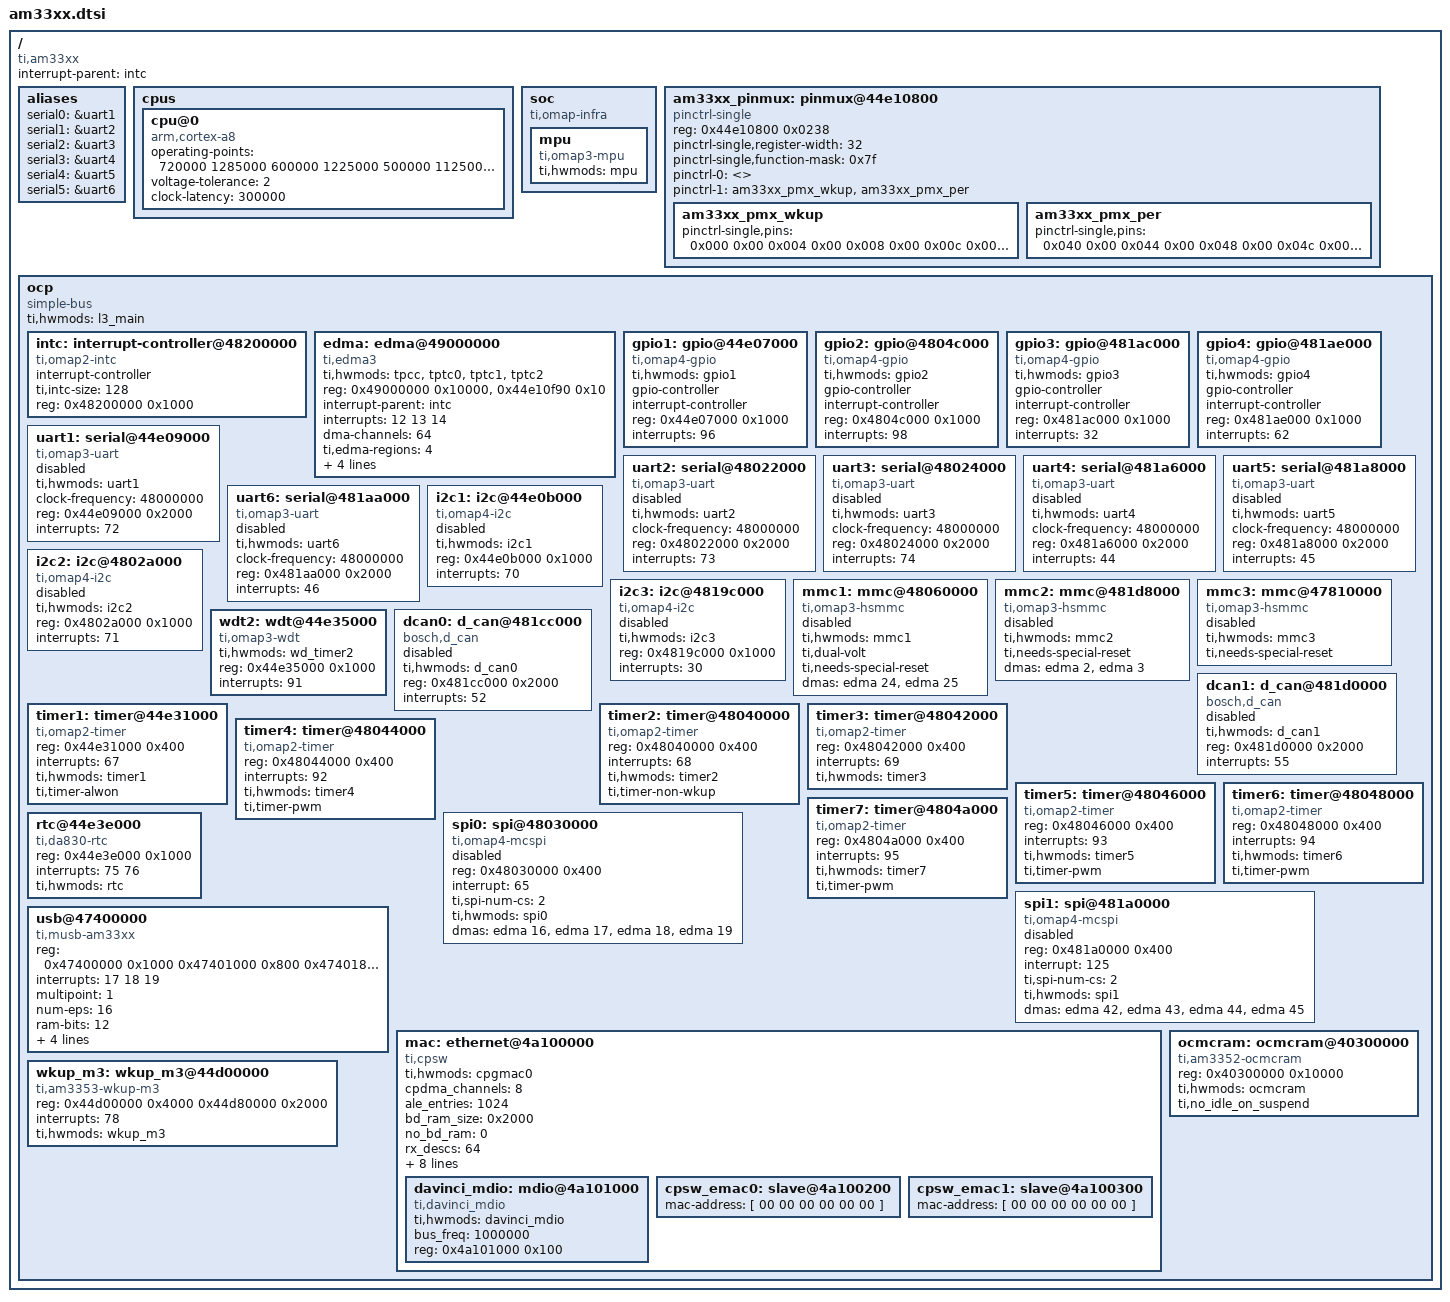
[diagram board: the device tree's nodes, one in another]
/*
 * Device Tree Source for AM33XX SoC
 *
 * Copyright (C) 2012 Texas Instruments Incorporated - http://www.ti.com/
 *
 * This file is licensed under the terms of the GNU General Public License
 * version 2.  This program is licensed "as is" without any warranty of any
 * kind, whether express or implied.
 */

/include/ "skeleton.dtsi"

/ {
	compatible = "ti,am33xx";
	interrupt-parent = <&intc>;

	aliases {
		serial0 = &uart1;
		serial1 = &uart2;
		serial2 = &uart3;
		serial3 = &uart4;
		serial4 = &uart5;
		serial5 = &uart6;
	};

	cpus {
		cpu@0 {
			compatible = "arm,cortex-a8";

			/*
			 * To consider voltage drop between PMIC and SoC,
			 * tolerance value is reduced to 2% from 4% and
			 * voltage value is increased as a precaution.
			 */
			operating-points = <
				/* kHz    uV */
				720000  1285000
				600000  1225000
				500000  1125000
				275000  1125000
			>;
			voltage-tolerance = <2>; /* 2 percentage */
			clock-latency = <300000>; /* From omap-cpufreq driver */
		};
	};

	/*
	 * The soc node represents the soc top level view. It is uses for IPs
	 * that are not memory mapped in the MPU view or for the MPU itself.
	 */
	soc {
		compatible = "ti,omap-infra";
		mpu {
			compatible = "ti,omap3-mpu";
			ti,hwmods = "mpu";
		};
	};

	am33xx_pinmux: pinmux@44e10800 {
		compatible = "pinctrl-single";
		reg = <0x44e10800 0x0238>;
		#address-cells = <1>;
		#size-cells = <0>;
		pinctrl-single,register-width = <32>;
		pinctrl-single,function-mask = <0x7f>;

                pinctrl-names = "default", "context";
		pinctrl-0 = <>;
		pinctrl-1 = <&am33xx_pmx_wkup &am33xx_pmx_per>;

		am33xx_pmx_wkup: am33xx_pmx_wkup {
			pinctrl-single,pins = <
				0x000 0x00 /* GPMC_AD0 */
				0x004 0x00 /* GPMC_AD1 */
				0x008 0x00 /* GPMC_AD2 */
				0x00c 0x00 /* GPMC_AD3 */
				0x010 0x00 /* GPMC_AD4 */
				0x014 0x00 /* GPMC_AD5 */
				0x018 0x00 /* GPMC_AD6 */
				0x01c 0x00 /* GPMC_AD7 */
				0x020 0x00 /* GPMC_AD8 */
				0x024 0x00 /* GPMC_AD9 */
				0x028 0x00 /* GPMC_AD10 */
				0x02c 0x00 /* GPMC_AD11 */
				0x030 0x00 /* GPMC_AD12 */
				0x034 0x00 /* GPMC_AD13 */
				0x038 0x00 /* GPMC_AD14 */
				0x03c 0x00 /* GPMC_AD15 */
				0x07c 0x00 /* GPMC_CSN0 */
				0x080 0x00 /* GPMC_CSN1 */
				0x084 0x00 /* GPMC_CSN2 */
				0x088 0x00 /* GPMC_CSN3 */
				0x08c 0x00 /* GPMC_CLK */
				0x090 0x00 /* GPMC_ADVN_ALE */
				0x094 0x00 /* GPMC_OEN_REN */
				0x098 0x00 /* GPMC_WEN */
				0x09c 0x00 /* GPMC_BEN0_CLE */
				0x0a0 0x00 /* LCD_DATA0 */
				0x0a4 0x00 /* LCD_DATA1 */
				0x0a8 0x00 /* LCD_DATA2 */
				0x0ac 0x00 /* LCD_DATA3 */
				0x0b0 0x00 /* LCD_DATA4 */
				0x0b4 0x00 /* LCD_DATA5 */
				0x0b8 0x00 /* LCD_DATA6 */
				0x0bc 0x00 /* LCD_DATA7 */
				0x0c0 0x00 /* LCD_DATA8 */
				0x0c4 0x00 /* LCD_DATA9 */
				0x0c8 0x00 /* LCD_DATA10 */
				0x0cc 0x00 /* LCD_DATA11 */
				0x0d0 0x00 /* LCD_DATA12 */
				0x0d4 0x00 /* LCD_DATA13 */
				0x0d8 0x00 /* LCD_DATA14 */
				0x0dc 0x00 /* LCD_DATA15 */
				0x0e0 0x00 /* LCD_VSYNC */
				0x0e4 0x00 /* LCD_HSYNC */
				0x0e8 0x00 /* LCD_PCLK */
				0x0ec 0x00 /* LCD_AC_BIAS_EN */
				0x0f0 0x00 /* MMC0_DAT3 */
				0x0f4 0x00 /* MMC0_DAT2 */
				0x0f8 0x00 /* MMC0_DAT1 */
				0x0fc 0x00 /* MMC0_DAT0 */
				0x100 0x00 /* MMC0_CLK */
				0x104 0x00 /* MMC0_CMD */
				0x150 0x00 /* SPI0_SCLK */
				0x154 0x00 /* SPI0_D0 */
				0x158 0x00 /* SPI0_D1 */
				0x15c 0x00 /* SPI0_CS0 */
				0x160 0x00 /* SPI0_CS1 */
				0x164 0x00 /* ECAP0_IN_PWM0_OUT */
				0x168 0x00 /* UART0_CTSN */
				0x16c 0x00 /* UART0_RTSN */
				0x170 0x00 /* UART0_RXD */
				0x174 0x00 /* UART0_TXD */
				0x178 0x00 /* UART1_CTSN */
				0x17c 0x00 /* UART1_RTSN */
				0x180 0x00 /* UART1_RXD */
				0x184 0x00 /* UART1_TXD */
				0x188 0x00 /* I2C0_SDA */
				0x18c 0x00 /* I2C0_SCL */
				0x190 0x00 /* MCASP0_ACLKX */
				0x194 0x00 /* MCASP0_FSX */
				0x198 0x00 /* MCASP0_AXR0 */
				0x19c 0x00 /* MCASP0_AHCLKR */
				0x1a0 0x00 /* MCASP0_ACLKR */
				0x1a4 0x00 /* MCASP0_FSR */
				0x1a8 0x00 /* MCASP0_AXR1 */
				0x1ac 0x00 /* MCASP0_AHCLKX */
				0x1b0 0x00 /* XDMA_EVENT_INTR0 */
				0x1b4 0x00 /* XDMA_EVENT_INTR1 */
				0x1b8 0x00 /* WARMRSTN */
				0x1c0 0x00 /* NMIN */
				0x1d0 0x00 /* TMS */
				0x1d4 0x00 /* TDI */
				0x1d8 0x00 /* TDO */
				0x1dc 0x00 /* TCK */
				0x1e0 0x00 /* TRSTN */
				0x1e4 0x00 /* EMU0 */
				0x1e8 0x00 /* EMU1 */
				0x1f8 0x00 /* RTC_PWRONRSTN */
				0x1fc 0x00 /* PMIC_POWER_EN */
				0x200 0x00 /* EXT_WAKEUP */
				0x204 0x00 /* RTC_KALDO_ENN */
				0x21c 0x00 /* USB0_DRVVBUS */
				0x234 0x00 /* USB1_DRVVBUS */
			>;
		};

		am33xx_pmx_per: am33xx_pmx_per {
			pinctrl-single,pins = <
				0x040 0x00 /* GPMC_A0 */
				0x044 0x00 /* GPMC_A1 */
				0x048 0x00 /* GPMC_A2 */
				0x04c 0x00 /* GPMC_A3 */
				0x050 0x00 /* GPMC_A4 */
				0x054 0x00 /* GPMC_A5 */
				0x058 0x00 /* GPMC_A6 */
				0x05c 0x00 /* GPMC_A7 */
				0x060 0x00 /* GPMC_A8 */
				0x064 0x00 /* GPMC_A9 */
				0x068 0x00 /* GPMC_A10 */
				0x06c 0x00 /* GPMC_A11 */
				0x070 0x00 /* GPMC_WAIT0 */
				0x074 0x00 /* GPMC_WPN */
				0x078 0x00 /* GPMC_BEN1 */
				0x108 0x00 /* MII1_COL */
				0x10c 0x00 /* MII1_CRS */
				0x110 0x00 /* MII1_RXERR */
				0x114 0x00 /* MII1_TXEN */
				0x118 0x00 /* MII1_RXDV */
				0x11c 0x00 /* MII1_TXD3 */
				0x120 0x00 /* MII1_TXD2 */
				0x124 0x00 /* MII1_TXD1 */
				0x128 0x00 /* MII1_TXD0 */
				0x12c 0x00 /* MII1_TXCLK */
				0x130 0x00 /* MII1_RXCLK */
				0x134 0x00 /* MII1_RXD3 */
				0x138 0x00 /* MII1_RXD2 */
				0x13c 0x00 /* MII1_RXD1 */
				0x140 0x00 /* MII1_RXD0 */
				0x144 0x00 /* MII1_REFCLK */
				0x148 0x00 /* MDIO_DATA */
				0x14c 0x00 /* MDIO_CLK */
			>;
		};
	};

	/*
	 * XXX: Use a flat representation of the AM33XX interconnect.
	 * The real AM33XX interconnect network is quite complex.Since
	 * that will not bring real advantage to represent that in DT
	 * for the moment, just use a fake OCP bus entry to represent
	 * the whole bus hierarchy.
	 */
	ocp {
		compatible = "simple-bus";
		#address-cells = <1>;
		#size-cells = <1>;
		ranges;
		ti,hwmods = "l3_main";

		intc: interrupt-controller@48200000 {
			compatible = "ti,omap2-intc";
			interrupt-controller;
			#interrupt-cells = <1>;
			ti,intc-size = <128>;
			reg = <0x48200000 0x1000>;
		};

		edma: edma@49000000 {
			compatible = "ti,edma3";
			ti,hwmods = "tpcc", "tptc0", "tptc1", "tptc2";
			reg =	<0x49000000 0x10000>,
				<0x44e10f90 0x10>;
			interrupt-parent = <&intc>;
			interrupts = <12 13 14>;
			#dma-cells = <1>;
			dma-channels = <64>;
			ti,edma-regions = <4>;
			ti,edma-slots = <256>;
			ti,edma-queue-tc-map = <0 0
						1 1
						2 2>;
			ti,edma-queue-priority-map = <0 0
						      1 1
						      2 2>;
			ti,edma-default-queue = <0>;
		};

		gpio1: gpio@44e07000 {
			compatible = "ti,omap4-gpio";
			ti,hwmods = "gpio1";
			gpio-controller;
			#gpio-cells = <2>;
			interrupt-controller;
			#interrupt-cells = <1>;
			reg = <0x44e07000 0x1000>;
			interrupts = <96>;
		};

		gpio2: gpio@4804c000 {
			compatible = "ti,omap4-gpio";
			ti,hwmods = "gpio2";
			gpio-controller;
			#gpio-cells = <2>;
			interrupt-controller;
			#interrupt-cells = <1>;
			reg = <0x4804c000 0x1000>;
			interrupts = <98>;
		};

		gpio3: gpio@481ac000 {
			compatible = "ti,omap4-gpio";
			ti,hwmods = "gpio3";
			gpio-controller;
			#gpio-cells = <2>;
			interrupt-controller;
			#interrupt-cells = <1>;
			reg = <0x481ac000 0x1000>;
			interrupts = <32>;
		};

		gpio4: gpio@481ae000 {
			compatible = "ti,omap4-gpio";
			ti,hwmods = "gpio4";
			gpio-controller;
			#gpio-cells = <2>;
			interrupt-controller;
			#interrupt-cells = <1>;
			reg = <0x481ae000 0x1000>;
			interrupts = <62>;
		};

		uart1: serial@44e09000 {
			compatible = "ti,omap3-uart";
			ti,hwmods = "uart1";
			clock-frequency = <48000000>;
			reg = <0x44e09000 0x2000>;
			interrupts = <72>;
			status = "disabled";
		};

		uart2: serial@48022000 {
			compatible = "ti,omap3-uart";
			ti,hwmods = "uart2";
			clock-frequency = <48000000>;
			reg = <0x48022000 0x2000>;
			interrupts = <73>;
			status = "disabled";
		};

		uart3: serial@48024000 {
			compatible = "ti,omap3-uart";
			ti,hwmods = "uart3";
			clock-frequency = <48000000>;
			reg = <0x48024000 0x2000>;
			interrupts = <74>;
			status = "disabled";
		};

		uart4: serial@481a6000 {
			compatible = "ti,omap3-uart";
			ti,hwmods = "uart4";
			clock-frequency = <48000000>;
			reg = <0x481a6000 0x2000>;
			interrupts = <44>;
			status = "disabled";
		};

		uart5: serial@481a8000 {
			compatible = "ti,omap3-uart";
			ti,hwmods = "uart5";
			clock-frequency = <48000000>;
			reg = <0x481a8000 0x2000>;
			interrupts = <45>;
			status = "disabled";
		};

		uart6: serial@481aa000 {
			compatible = "ti,omap3-uart";
			ti,hwmods = "uart6";
			clock-frequency = <48000000>;
			reg = <0x481aa000 0x2000>;
			interrupts = <46>;
			status = "disabled";
		};

		i2c1: i2c@44e0b000 {
			compatible = "ti,omap4-i2c";
			#address-cells = <1>;
			#size-cells = <0>;
			ti,hwmods = "i2c1";
			reg = <0x44e0b000 0x1000>;
			interrupts = <70>;
			status = "disabled";
		};

		i2c2: i2c@4802a000 {
			compatible = "ti,omap4-i2c";
			#address-cells = <1>;
			#size-cells = <0>;
			ti,hwmods = "i2c2";
			reg = <0x4802a000 0x1000>;
			interrupts = <71>;
			status = "disabled";
		};

		i2c3: i2c@4819c000 {
			compatible = "ti,omap4-i2c";
			#address-cells = <1>;
			#size-cells = <0>;
			ti,hwmods = "i2c3";
			reg = <0x4819c000 0x1000>;
			interrupts = <30>;
			status = "disabled";
		};

		mmc1: mmc@48060000 {
			compatible = "ti,omap3-hsmmc";
			ti,hwmods = "mmc1";
			ti,dual-volt;
			ti,needs-special-reset;
			dmas = <&edma 24
				&edma 25>;
			dma-names = "tx", "rx";
			status = "disabled";
		};

		mmc2: mmc@481d8000 {
			compatible = "ti,omap3-hsmmc";
			ti,hwmods = "mmc2";
			ti,needs-special-reset;
			dmas = <&edma 2
				&edma 3>;
			dma-names = "tx", "rx";
			status = "disabled";
		};

		mmc3: mmc@47810000 {
			compatible = "ti,omap3-hsmmc";
			ti,hwmods = "mmc3";
			ti,needs-special-reset;
			status = "disabled";
		};

		wdt2: wdt@44e35000 {
			compatible = "ti,omap3-wdt";
			ti,hwmods = "wd_timer2";
			reg = <0x44e35000 0x1000>;
			interrupts = <91>;
		};

		dcan0: d_can@481cc000 {
			compatible = "bosch,d_can";
			ti,hwmods = "d_can0";
			reg = <0x481cc000 0x2000>;
			interrupts = <52>;
			status = "disabled";
		};

		dcan1: d_can@481d0000 {
			compatible = "bosch,d_can";
			ti,hwmods = "d_can1";
			reg = <0x481d0000 0x2000>;
			interrupts = <55>;
			status = "disabled";
		};

		timer1: timer@44e31000 {
			compatible = "ti,omap2-timer";
			reg = <0x44e31000 0x400>;
			interrupts = <67>;
			ti,hwmods = "timer1";
			ti,timer-alwon;
		};

		timer2: timer@48040000 {
			compatible = "ti,omap2-timer";
			reg = <0x48040000 0x400>;
			interrupts = <68>;
			ti,hwmods = "timer2";
			ti,timer-non-wkup;
		};

		timer3: timer@48042000 {
			compatible = "ti,omap2-timer";
			reg = <0x48042000 0x400>;
			interrupts = <69>;
			ti,hwmods = "timer3";
		};

		timer4: timer@48044000 {
			compatible = "ti,omap2-timer";
			reg = <0x48044000 0x400>;
			interrupts = <92>;
			ti,hwmods = "timer4";
			ti,timer-pwm;
		};

		timer5: timer@48046000 {
			compatible = "ti,omap2-timer";
			reg = <0x48046000 0x400>;
			interrupts = <93>;
			ti,hwmods = "timer5";
			ti,timer-pwm;
		};

		timer6: timer@48048000 {
			compatible = "ti,omap2-timer";
			reg = <0x48048000 0x400>;
			interrupts = <94>;
			ti,hwmods = "timer6";
			ti,timer-pwm;
		};

		timer7: timer@4804a000 {
			compatible = "ti,omap2-timer";
			reg = <0x4804a000 0x400>;
			interrupts = <95>;
			ti,hwmods = "timer7";
			ti,timer-pwm;
		};

		rtc@44e3e000 {
			compatible = "ti,da830-rtc";
			reg = <0x44e3e000 0x1000>;
			interrupts = <75
				      76>;
			ti,hwmods = "rtc";
		};

		spi0: spi@48030000 {
			compatible = "ti,omap4-mcspi";
			#address-cells = <1>;
			#size-cells = <0>;
			reg = <0x48030000 0x400>;
			interrupt = <65>;
			ti,spi-num-cs = <2>;
			ti,hwmods = "spi0";
			dmas = <&edma 16
				&edma 17
				&edma 18
				&edma 19>;
			dma-names = "tx0", "rx0", "tx1", "rx1";
			status = "disabled";
		};

		spi1: spi@481a0000 {
			compatible = "ti,omap4-mcspi";
			#address-cells = <1>;
			#size-cells = <0>;
			reg = <0x481a0000 0x400>;
			interrupt = <125>;
			ti,spi-num-cs = <2>;
			ti,hwmods = "spi1";
			dmas = <&edma 42
				&edma 43
				&edma 44
				&edma 45>;
			dma-names = "tx0", "rx0", "tx1", "rx1";
			status = "disabled";
		};

		usb@47400000 {
			compatible = "ti,musb-am33xx";
			reg = <0x47400000 0x1000	/* usbss */
			       0x47401000 0x800		/* musb instance 0 */
			       0x47401800 0x800>;	/* musb instance 1 */
			interrupts = <17		/* usbss */
				      18		/* musb instance 0 */
				      19>;		/* musb instance 1 */
			multipoint = <1>;
			num-eps = <16>;
			ram-bits = <12>;
			port0-mode = <3>;
			port1-mode = <3>;
			power = <250>;
			ti,hwmods = "usb_otg_hs";
		};

		mac: ethernet@4a100000 {
			compatible = "ti,cpsw";
			ti,hwmods = "cpgmac0";
			cpdma_channels = <8>;
			ale_entries = <1024>;
			bd_ram_size = <0x2000>;
			no_bd_ram = <0>;
			rx_descs = <64>;
			mac_control = <0x20>;
			slaves = <2>;
			cpts_active_slave = <0>;
			cpts_clock_mult = <0x80000000>;
			cpts_clock_shift = <29>;
			reg = <0x4a100000 0x800
			       0x4a101200 0x100>;
			#address-cells = <1>;
			#size-cells = <1>;
			interrupt-parent = <&intc>;
			/*
			 * c0_rx_thresh_pend
			 * c0_rx_pend
			 * c0_tx_pend
			 * c0_misc_pend
			 */
			interrupts = <40 41 42 43>;
			ranges;

			davinci_mdio: mdio@4a101000 {
				compatible = "ti,davinci_mdio";
				#address-cells = <1>;
				#size-cells = <0>;
				ti,hwmods = "davinci_mdio";
				bus_freq = <1000000>;
				reg = <0x4a101000 0x100>;
			};

			cpsw_emac0: slave@4a100200 {
				/* Filled in by U-Boot */
				mac-address = [ 00 00 00 00 00 00 ];
			};

			cpsw_emac1: slave@4a100300 {
				/* Filled in by U-Boot */
				mac-address = [ 00 00 00 00 00 00 ];
			};
		};

		ocmcram: ocmcram@40300000 {
			compatible = "ti,am3352-ocmcram";
			reg = <0x40300000 0x10000>;
			ti,hwmods = "ocmcram";
			ti,no_idle_on_suspend;
		};

		wkup_m3: wkup_m3@44d00000 {
			compatible = "ti,am3353-wkup-m3";
			reg = <0x44d00000 0x4000	/* M3 UMEM */
			       0x44d80000 0x2000>;	/* M3 DMEM */
			interrupts = <78>;
			ti,hwmods = "wkup_m3";
		};
	};
};
